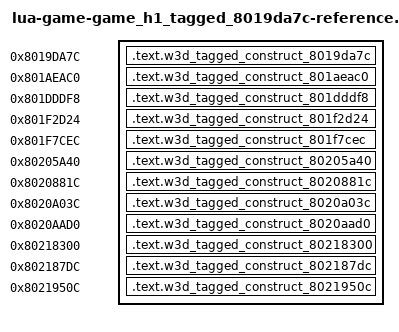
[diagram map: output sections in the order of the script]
/* Generated reference-only placements. All bodies are source-built. */
OUTPUT_FORMAT("elf32-powerpc")
OUTPUT_ARCH(powerpc)
ENTRY(w3d_tagged_construct_8019da7c)
_SDA_BASE_ = 0x804b2540;
_SDA2_BASE_ = 0x804c2540;
w3d_aligned_allocate = 0x801fe2a8;
w3d_construct_802109dc = 0x802109dc;
w3d_string_assign_range = 0x8020bdf4;
w3d_string_column_format_803b2e04 = 0x803b2e04;
w3d_string_default = 0x803426b8;
w3d_string_from_text = 0x8020bb54;
w3d_string_unused_803b029c = 0x803b029c;
w3d_vtable_80411590 = 0x80411590;
w3d_vtable_80413760 = 0x80413760;
w3d_vtable_804137b0 = 0x804137b0;
w3d_vtable_80414170 = 0x80414170;
w3d_vtable_804141b8 = 0x804141b8;
w3d_vtable_80416a10 = 0x80416a10;
w3d_vtable_80417d10 = 0x80417d10;
w3d_vtable_80417d40 = 0x80417d40;
w3d_vtable_80418080 = 0x80418080;
w3d_vtable_804180a8 = 0x804180a8;
w3d_vtable_80418110 = 0x80418110;
w3d_vtable_804181c0 = 0x804181c0;
w3d_vtable_80418490 = 0x80418490;
w3d_vtable_804190f0 = 0x804190f0;
w3d_vtable_80419138 = 0x80419138;
w3d_vtable_804192f8 = 0x804192f8;
w3d_vtable_80419388 = 0x80419388;
w3d_vtable_804193d8 = 0x804193d8;
w3d_vtable_80419430 = 0x80419430;
w3d_vtable_804197a8 = 0x804197a8;
w3d_vtable_80419810 = 0x80419810;
w3d_vtable_80419858 = 0x80419858;
SECTIONS {
  .text.w3d_tagged_construct_8019da7c 0x8019da7c : { *(.text.w3d_tagged_construct_8019da7c) }
  .text.w3d_tagged_construct_801aeac0 0x801aeac0 : { *(.text.w3d_tagged_construct_801aeac0) }
  .text.w3d_tagged_construct_801dddf8 0x801dddf8 : { *(.text.w3d_tagged_construct_801dddf8) }
  .text.w3d_tagged_construct_801f2d24 0x801f2d24 : { *(.text.w3d_tagged_construct_801f2d24) }
  .text.w3d_tagged_construct_801f7cec 0x801f7cec : { *(.text.w3d_tagged_construct_801f7cec) }
  .text.w3d_tagged_construct_80205a40 0x80205a40 : { *(.text.w3d_tagged_construct_80205a40) }
  .text.w3d_tagged_construct_8020881c 0x8020881c : { *(.text.w3d_tagged_construct_8020881c) }
  .text.w3d_tagged_construct_8020a03c 0x8020a03c : { *(.text.w3d_tagged_construct_8020a03c) }
  .text.w3d_tagged_construct_8020aad0 0x8020aad0 : { *(.text.w3d_tagged_construct_8020aad0) }
  .text.w3d_tagged_construct_80218300 0x80218300 : { *(.text.w3d_tagged_construct_80218300) }
  .text.w3d_tagged_construct_802187dc 0x802187dc : { *(.text.w3d_tagged_construct_802187dc) }
  .text.w3d_tagged_construct_8021950c 0x8021950c : { *(.text.w3d_tagged_construct_8021950c) }
  /DISCARD/ : { *(.text*) *(.rodata*) *(.data*) *(.bss*) *(.sdata*) *(.sbss*) *(.comment) }
}
